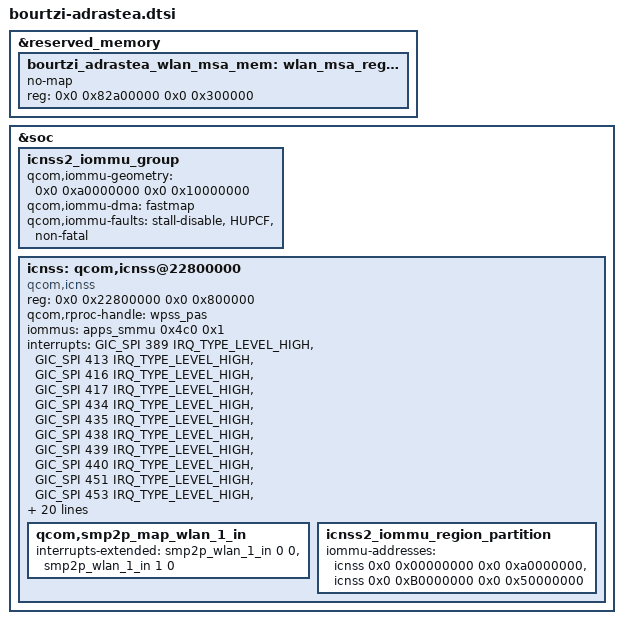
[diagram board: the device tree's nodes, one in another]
// SPDX-License-Identifier: BSD-3-Clause

/*
 * Copyright (c) Qualcomm Technologies, Inc. and/or its subsidiaries.
 */

#include <dt-bindings/interrupt-controller/arm-gic.h>

&reserved_memory {
	bourtzi_adrastea_wlan_msa_mem: wlan_msa_region@82a00000 {
		no-map;
		reg = <0x0 0x82a00000 0x0 0x300000>;
	};
};

&soc {

	icnss2_iommu_group: icnss2_iommu_group {
		qcom,iommu-geometry = <0x0 0xa0000000 0x0 0x10000000>;
		qcom,iommu-dma = "fastmap";
		qcom,iommu-faults = "stall-disable", "HUPCF", "non-fatal";
	};

	icnss: qcom,icnss@22800000 {
		compatible = "qcom,icnss";
		reg = <0x0 0x22800000 0x0 0x800000>;
		reg-names = "membase";
		qcom,rproc-handle = <&wpss_pas>;
		iommus = <&apps_smmu 0x4c0 0x1>;

		interrupts = <GIC_SPI 389 IRQ_TYPE_LEVEL_HIGH /* CE0 */ >,
			     <GIC_SPI 413 IRQ_TYPE_LEVEL_HIGH /* CE1 */ >,
			     <GIC_SPI 416 IRQ_TYPE_LEVEL_HIGH /* CE2 */ >,
			     <GIC_SPI 417 IRQ_TYPE_LEVEL_HIGH /* CE3 */ >,
			     <GIC_SPI 434 IRQ_TYPE_LEVEL_HIGH /* CE4 */ >,
			     <GIC_SPI 435 IRQ_TYPE_LEVEL_HIGH /* CE5 */ >,
			     <GIC_SPI 438 IRQ_TYPE_LEVEL_HIGH /* CE6 */ >,
			     <GIC_SPI 439 IRQ_TYPE_LEVEL_HIGH /* CE7 */ >,
			     <GIC_SPI 440 IRQ_TYPE_LEVEL_HIGH /* CE8 */ >,
			     <GIC_SPI 451 IRQ_TYPE_LEVEL_HIGH /* CE9 */ >,
			     <GIC_SPI 453 IRQ_TYPE_LEVEL_HIGH /* CE10 */ >,
			     <GIC_SPI 454 IRQ_TYPE_LEVEL_HIGH /* CE11 */ >;

		qcom,iommu-group = <&icnss2_iommu_group>;
		dma-coherent;
		memory-region = <&icnss2_iommu_region_partition>;
		qcom,fw-prefix;
		qcom,wlan;
		wpss-support-enable;
		bdf-download-support;
		qcom,wlan-msa-fixed-region = <&bourtzi_adrastea_wlan_msa_mem>;
		vdd-cx-mx-supply = <&L11B>;
		vdd-1.8-xo-supply = <&L18B>;
		vdd-1.3-rfa-supply = <&L14B>;
		vdd-3.3-ch1-supply = <&L24B>;
		vdd-3.3-ch0-supply = <&L7E>;
		qcom,vdd-cx-mx-config = <0 0>;
		qcom,vdd-3.3-ch1-config = <3000000 3312000 1>;
		qcom,vdd-3.3-ch0-config = <3000000 3312000 1>;

		qcom,smem-states = <&smp2p_wlan_1_out 0>;
		qcom,smem-state-names = "wlan-smp2p-out";

		qcom,smp2p_map_wlan_1_in {
			interrupts-extended = <&smp2p_wlan_1_in 0 0>,
					      <&smp2p_wlan_1_in 1 0>;
			interrupt-names = "qcom,smp2p-force-fatal-error",
					  "qcom,smp2p-early-crash-ind";
		};

		icnss2_iommu_region_partition: icnss2_iommu_region_partition {
			iommu-addresses = <&icnss 0x0 0x00000000 0x0 0xa0000000>,
					<&icnss 0x0 0xB0000000 0x0 0x50000000>;
		};
	};
};
